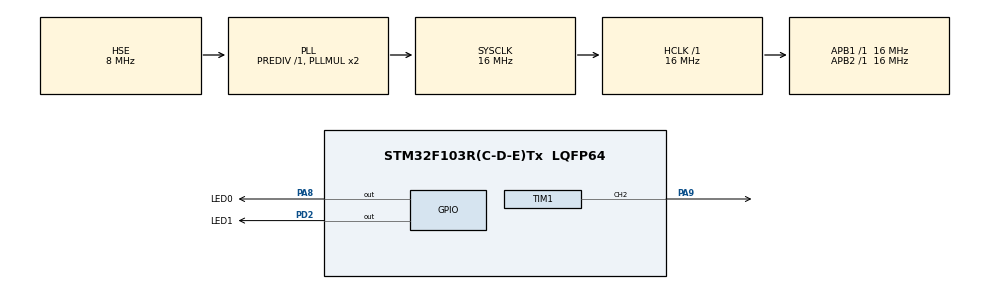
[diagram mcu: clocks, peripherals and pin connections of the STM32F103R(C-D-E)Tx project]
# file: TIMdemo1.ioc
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Mcu.Family=STM32F1
Mcu.Name=STM32F103R(C-D-E)Tx
Mcu.Package=LQFP64
NVIC.PriorityGroup=NVIC_PRIORITYGROUP_4
NVIC.TIM1_BRK_IRQn=true\:0\:0\:false\:false\:true\:true\:true
NVIC.TIM1_CC_IRQn=true\:0\:0\:false\:false\:true\:true\:true
NVIC.TIM1_TRG_COM_IRQn=true\:0\:0\:false\:false\:true\:true\:true
NVIC.TIM1_UP_IRQn=true\:0\:0\:false\:false\:true\:true\:true
NVIC.TIM2_IRQn=true\:0\:0\:false\:false\:true\:true\:true
NVIC.TIM3_IRQn=true\:0\:0\:false\:false\:true\:true\:true
PA8.GPIO_Label=LED0
PA8.Signal=GPIO_Output
PA9.Signal=S_TIM1_CH2
PC14-OSC32_IN.Mode=LSE-External-Oscillator
PC14-OSC32_IN.Signal=RCC_OSC32_IN
PC15-OSC32_OUT.Mode=LSE-External-Oscillator
PC15-OSC32_OUT.Signal=RCC_OSC32_OUT
PD0-OSC_IN.Mode=HSE-External-Oscillator
PD0-OSC_IN.Signal=RCC_OSC_IN
PD1-OSC_OUT.Mode=HSE-External-Oscillator
PD1-OSC_OUT.Signal=RCC_OSC_OUT
PD2.GPIO_Label=LED1
PD2.Signal=GPIO_Output
ProjectManager.HeapSize=0x200
ProjectManager.StackSize=0x400
ProjectManager.TargetToolchain=MDK-ARM V5
RCC.AHBFreq_Value=16000000
RCC.APB1Freq_Value=16000000
RCC.APB1TimFreq_Value=16000000
RCC.APB2Freq_Value=16000000
RCC.APB2TimFreq_Value=16000000
RCC.HCLKFreq_Value=16000000
RCC.PLLSourceVirtual=RCC_PLLSOURCE_HSE
RCC.SYSCLKFreq_VALUE=16000000
RCC.SYSCLKSource=RCC_SYSCLKSOURCE_PLLCLK
RCC.USBFreq_Value=16000000
SH.S_TIM1_CH2.0=TIM1_CH2,PWM Generation2 CH2
TIM1.Channel-PWM\ Generation2\ CH2=TIM_CHANNEL_2
TIM1.Period=299
TIM1.Prescaler=31999
TIM1.Pulse-PWM\ Generation2\ CH2=500
TIM2.Period=199
TIM2.Prescaler=31999
TIM3.Period=999
TIM3.Prescaler=31999
VP_SYS_VS_ND.Mode=No_Debug
VP_TIM1_VS_ClockSourceINT.Mode=Internal
VP_TIM2_VS_ClockSourceINT.Mode=Internal
VP_TIM3_VS_ClockSourceINT.Mode=Internal
board=custom

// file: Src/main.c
/* USER CODE BEGIN Header */
/**
  ******************************************************************************
  * @file           : main.c
  * @brief          : Main program body
  ******************************************************************************
  * @attention
  *
  * <h2><center>&copy; Copyright (c) 2020 STMicroelectronics.
  * All rights reserved.</center></h2>
  *
  * This software component is licensed by ST under BSD 3-Clause license,
  * the "License"; You may not use this file except in compliance with the
  * License. You may obtain a copy of the License at:
  *                        opensource.org/licenses/BSD-3-Clause
  *
  ******************************************************************************
  */
/* USER CODE END Header */

#include "main.h"
#include "tim.h"
#include "gpio.h"

/* USER CODE BEGIN Includes */
void changeFP(int f , int p){
	prescalermf = f;
	period = p;
	MX_TIM1_Init();
}
/* USER CODE END Includes */

/* USER CODE BEGIN PM */
void HAL_TIM_PeriodElapsedCallback(TIM_HandleTypeDef *htim){
  if(htim->Instance == TIM2){
    HAL_GPIO_TogglePin(LED1_GPIO_Port,LED1_Pin);
  }

  if(htim->Instance == TIM3){
    HAL_GPIO_TogglePin(LED0_GPIO_Port,LED0_Pin);
  }

}
/* USER CODE END PM */

void SystemClock_Config(void);

int main(void)
{
  /* USER CODE BEGIN 1 */
//	int pwm = 0 ;
  /* USER CODE END 1 */

  /* MCU Configuration--------------------------------------------------------*/

  /* Reset of all peripherals, Initializes the Flash interface and the Systick. */
  HAL_Init();

  /* Configure the system clock */
  SystemClock_Config();

  /* Initialize all configured peripherals */
  MX_GPIO_Init();
  MX_TIM2_Init();
  MX_TIM3_Init();
  MX_TIM1_Init();
  /* USER CODE BEGIN 2 */
  HAL_TIM_Base_Start_IT(&htim2);
  HAL_TIM_Base_Start_IT(&htim3);
	//HAL_TIM_PWM_Start(&htim1,TIM_CHANNE_1);
  /* USER CODE END 2 */

  /* Infinite loop */
  /* USER CODE BEGIN WHILE */

  while (1)
  {
	//	__HAL_TIM_SET_COMPARE(&htim1,TIM_CHANNE_2,(pwm++)%1000);
		HAL_Delay(5);
    /* USER CODE END WHILE */

  }
}

void SystemClock_Config(void)
{
  RCC_OscInitTypeDef RCC_OscInitStruct = {0};
  RCC_ClkInitTypeDef RCC_ClkInitStruct = {0};

  /** Initializes the CPU, AHB and APB busses clocks
  */
  RCC_OscInitStruct.OscillatorType = RCC_OSCILLATORTYPE_HSE;
  RCC_OscInitStruct.HSEState = RCC_HSE_ON;
  RCC_OscInitStruct.HSEPredivValue = RCC_HSE_PREDIV_DIV1;
  RCC_OscInitStruct.HSIState = RCC_HSI_ON;
  RCC_OscInitStruct.PLL.PLLState = RCC_PLL_ON;
  RCC_OscInitStruct.PLL.PLLSource = RCC_PLLSOURCE_HSE;
  RCC_OscInitStruct.PLL.PLLMUL = RCC_PLL_MUL2;
  if (HAL_RCC_OscConfig(&RCC_OscInitStruct) != HAL_OK)
  {
    Error_Handler();
  }
  /** Initializes the CPU, AHB and APB busses clocks
  */
  RCC_ClkInitStruct.ClockType = RCC_CLOCKTYPE_HCLK|RCC_CLOCKTYPE_SYSCLK
                              |RCC_CLOCKTYPE_PCLK1|RCC_CLOCKTYPE_PCLK2;
  RCC_ClkInitStruct.SYSCLKSource = RCC_SYSCLKSOURCE_PLLCLK;
  RCC_ClkInitStruct.AHBCLKDivider = RCC_SYSCLK_DIV1;
  RCC_ClkInitStruct.APB1CLKDivider = RCC_HCLK_DIV1;
  RCC_ClkInitStruct.APB2CLKDivider = RCC_HCLK_DIV1;

  if (HAL_RCC_ClockConfig(&RCC_ClkInitStruct, FLASH_LATENCY_0) != HAL_OK)
  {
    Error_Handler();
  }
}

void Error_Handler(void)
{
}

/************************ (C) COPYRIGHT STMicroelectronics *****END OF FILE****/
